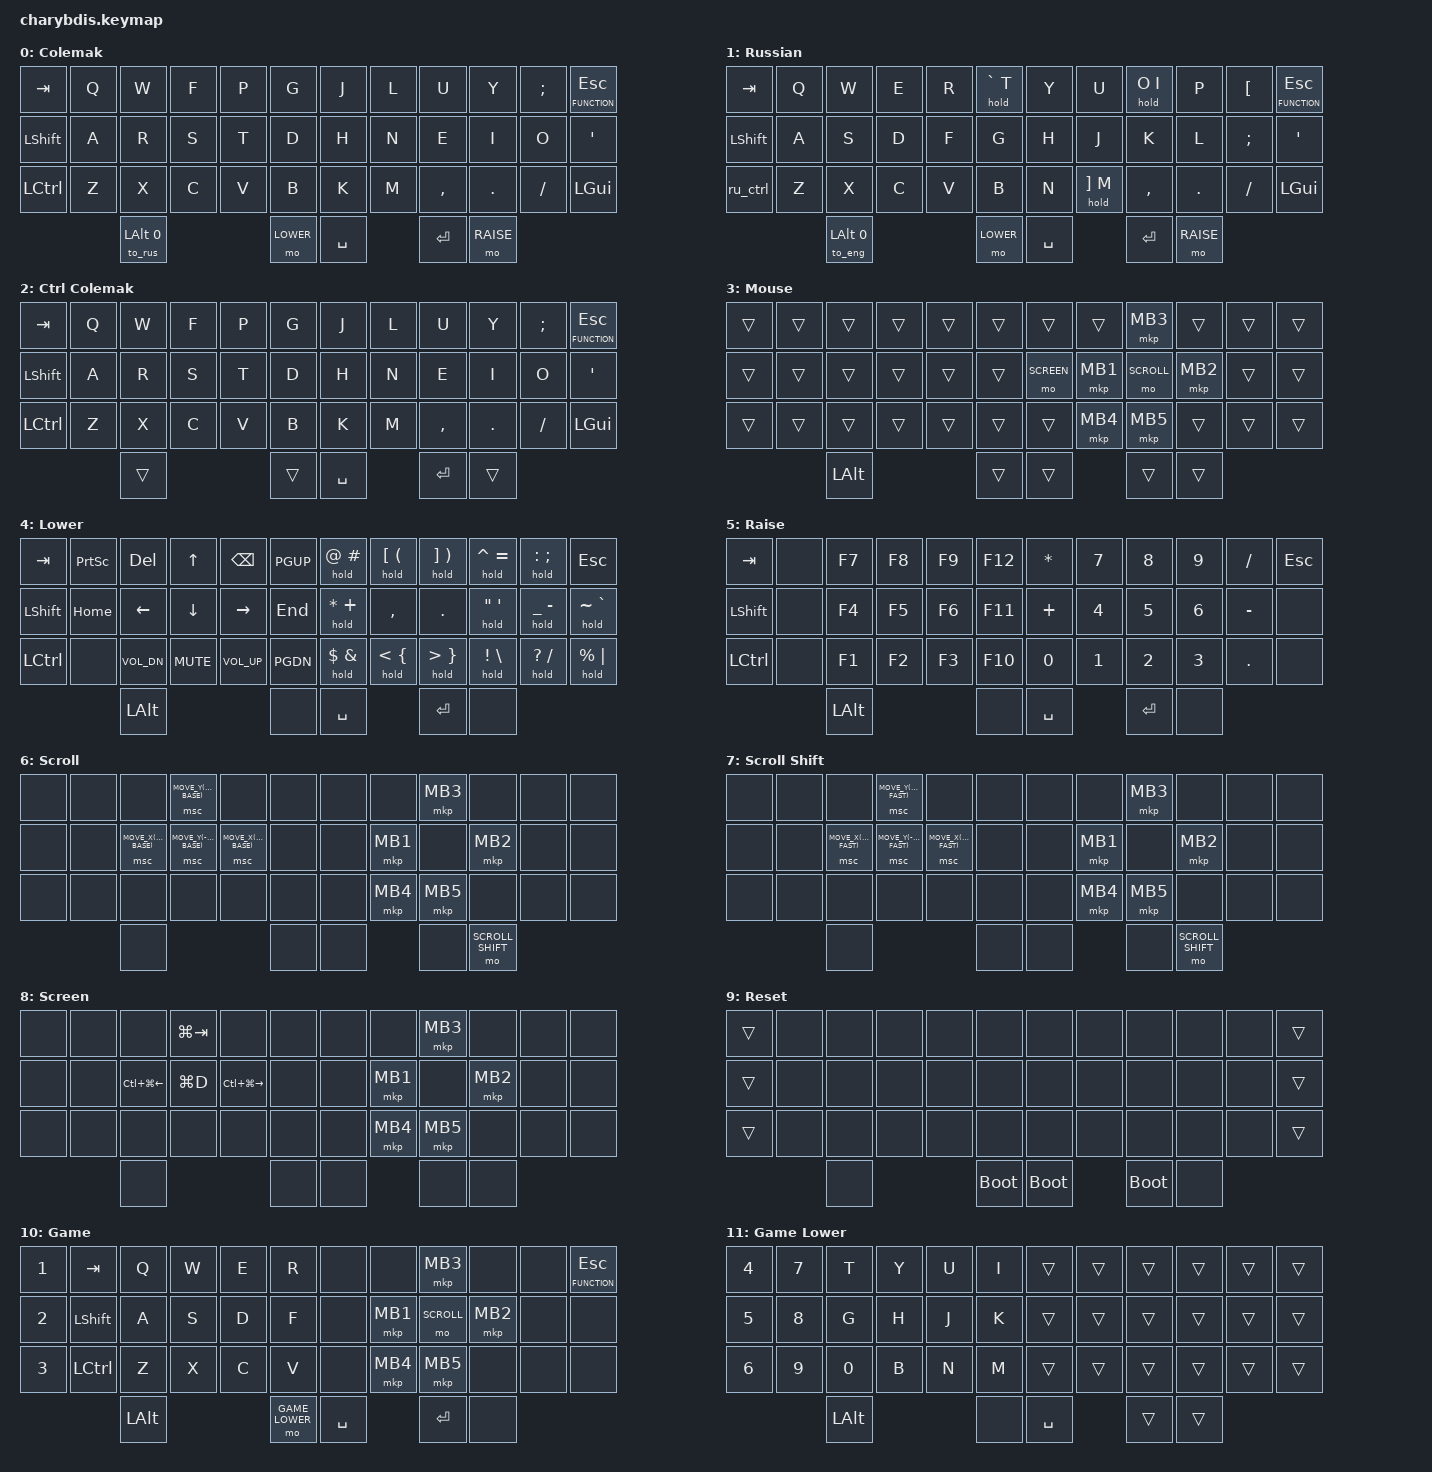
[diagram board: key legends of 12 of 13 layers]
#include <behaviors.dtsi>
#include <dt-bindings/zmk/keys.h>
#include <dt-bindings/zmk/pointing.h>
#include "behaviors/behavior_esc_layer_switch.dtsi"
#include "behaviors/behavior_ru_ctrl.dtsi"

#define COLEMAK 0
#define RUSSIAN 1
#define CTRL_COLEMAK 2
#define MOUSE 3
#define LOWER 4
#define RAISE 5
#define SCROLL 6
#define SCROLL_SHIFT 7
#define SCREEN 8
#define RESET 9
#define GAME 10
#define GAME_LOWER 11
#define FUNCTION 12

#define MOVE_BASE (ZMK_POINTING_DEFAULT_MOVE_VAL)
/* Legacy wheel ticks (smooth scroll off on dongle — ZMK #3383). *16 was hi-res only. */
#define SCROLL_BASE (ZMK_POINTING_DEFAULT_SCRL_VAL / 2)
#define SCROLL_FAST (SCROLL_BASE * 3)

/ {
  combos {
    compatible = "zmk,combos";
    timeout-ms = <20>;
    require-prior-idle-ms = <250>;

    combo_reset_layer_left {
      key-positions = <20 24>;
      bindings = <&to RESET>;
    };
    combo_reset_layer_right {
      key-positions = <25 29>;
      bindings = <&to RESET>;
    };
    combo_reset_central {
      key-positions = <37 38>;
      bindings = <&bootloader>;
      require-prior-idle-ms = <2000>;
    };
    combo_esc {
      key-positions = <1 2>;
      bindings = <&kp ESCAPE>;
    };
    combo_tab {
      key-positions = <2 3>;
      bindings = <&kp TAB>;
    };
    combo_cdel {
      key-positions = <11 12>;
      bindings = <&kp LC(BACKSPACE)>;
    };
    combo_unlock {
      key-positions = <0 4>;
      bindings = <&studio_unlock>;
    };
  };

  chosen {
    zmk,physical-layout = &charybdis_6col_layout;
  };

  keymap {
    compatible = "zmk,keymap";

    Colemak {
      display-name = "Colemak";
      bindings = <
        &kp TAB    &kp Q  &kp W  &kp F  &kp P  &kp G     &kp J  &kp L  &kp U     &kp Y    &kp SEMI  &lt FUNCTION ESCAPE
        &kp LSHFT  &kp A  &kp R  &kp S  &kp T  &kp D     &kp H  &kp N  &kp E     &kp I    &kp O     &kp SQT
        &kp LCTRL  &kp Z  &kp X  &kp C  &kp V  &kp B     &kp K  &kp M  &kp COMMA &kp DOT  &kp FSLH  &kp LGUI
                            &to_rus LALT 0  &mo LOWER  &kp SPACE     &kp RET  &mo RAISE
      >;
    };

    Russian {
      display-name = "Russian";
      bindings = <
        &kp TAB    &kp Q  &kp W  &kp E  &kp R  &hold GRAVE T  &kp Y  &kp U       &hold O I   &kp P    &kp LBKT  &lt FUNCTION ESCAPE
        &kp LSHFT  &kp A  &kp S  &kp D  &kp F  &kp G          &kp H  &kp J       &kp K       &kp L    &kp SEMI  &kp SQT
        &ru_ctrl  &kp Z  &kp X  &kp C  &kp V  &kp B          &kp N  &hold RBKT M &kp COMMA  &kp DOT  &kp FSLH  &kp LGUI
                            &to_eng LALT 0  &mo LOWER  &kp SPACE     &kp RET  &mo RAISE
      >;
    };

    /* Below Mouse/Lower/Raise so Ctrl-first chords still see those layers. */
    CtrlColemak {
      display-name = "Ctrl Colemak";
      bindings = <
        &kp TAB    &kp Q  &kp W  &kp F  &kp P  &kp G     &kp J  &kp L  &kp U     &kp Y    &kp SEMI  &lt FUNCTION ESCAPE
        &kp LSHFT  &kp A  &kp R  &kp S  &kp T  &kp D     &kp H  &kp N  &kp E     &kp I    &kp O     &kp SQT
        &kp LCTRL  &kp Z  &kp X  &kp C  &kp V  &kp B     &kp K  &kp M  &kp COMMA &kp DOT  &kp FSLH  &kp LGUI
                            &trans  &trans  &kp SPACE     &kp RET  &trans
      >;
    };

    Mouse {
      display-name = "Mouse";
      bindings = <
        &trans  &trans  &trans  &trans  &trans  &trans     &trans  &trans   &mkp MB3  &trans   &trans  &trans
        &trans  &trans  &trans  &trans  &trans  &trans     &mo SCREEN  &mkp MB1  &mo SCROLL  &mkp MB2  &trans  &trans
        &trans  &trans  &trans  &trans  &trans  &trans     &trans  &mkp MB4  &mkp MB5  &trans   &trans  &trans
                        &kp LALT  &trans  &trans     &trans  &trans
      >;
    };

    Lower {
      display-name = "Lower";
      bindings = <
        &kp TAB    &kp PSCRN  &kp DEL  &kp UP  &kp BSPC  &kp PGUP     &hold AT HASH  &hold LBKT LPAR  &hold RBKT RPAR  &hold CARET EQUAL  &hold COLON SEMI  &kp ESCAPE
        &kp LSHFT  &kp HOME   &kp LEFT &kp DOWN &kp RIGHT &kp END      &hold ASTRK PLUS  &kp COMMA  &kp DOT  &hold DQT SQT  &hold UNDER MINUS  &hold TILDE GRAVE
        &kp LCTRL  &none      &kp C_VOL_DN  &kp C_MUTE  &kp C_VOL_UP  &kp PGDN   &hold DLLR AMPS  &hold LT LBRC  &hold GT RBRC  &hold EXCL BSLH  &hold QMARK FSLH  &hold PRCNT PIPE
                                &kp LALT  &none  &kp SPACE  &kp RET  &none
      >;
    };

    Raise {
      display-name = "Raise";
      bindings = <
        &kp TAB    &none  &kp F7  &kp F8  &kp F9  &kp F12     &kp ASTRK  &kp N7  &kp N8  &kp N9  &kp FSLH  &kp ESCAPE
        &kp LSHFT  &none  &kp F4  &kp F5  &kp F6  &kp F11     &kp PLUS  &kp N4  &kp N5  &kp N6  &kp MINUS  &none
        &kp LCTRL  &none  &kp F1  &kp F2  &kp F3  &kp F10     &kp N0    &kp N1  &kp N2  &kp N3  &kp DOT   &none
                            &kp LALT  &none  &kp SPACE  &kp RET  &none
      >;
    };

    Scroll {
      display-name = "Scroll";
      bindings = <
        &none  &none  &none  &msc MOVE_Y(SCROLL_BASE)   &none  &none     &none  &none   &mkp MB3  &none  &none  &none
        &none  &none  &msc MOVE_X(-SCROLL_BASE) &msc MOVE_Y(-SCROLL_BASE) &msc MOVE_X(SCROLL_BASE) &none  &none  &mkp MB1  &none  &mkp MB2  &none  &none
        &none  &none  &none  &none  &none  &none     &none  &mkp MB4  &mkp MB5  &none  &none  &none
                        &none  &none  &none     &none  &mo SCROLL_SHIFT
      >;
    };

    ScrollShift {
      display-name = "Scroll Shift";
      bindings = <
        &none  &none  &none  &msc MOVE_Y(SCROLL_FAST)   &none  &none     &none  &none   &mkp MB3  &none  &none  &none
        &none  &none  &msc MOVE_X(-SCROLL_FAST) &msc MOVE_Y(-SCROLL_FAST) &msc MOVE_X(SCROLL_FAST) &none  &none  &mkp MB1  &none  &mkp MB2  &none  &none
        &none  &none  &none  &none  &none  &none     &none  &mkp MB4  &mkp MB5  &none  &none  &none
                        &none  &none  &none     &none  &mo SCROLL_SHIFT
      >;
    };

    Screen {
      display-name = "Screen";
      bindings = <
        &none  &none  &none  &kp LG(TAB)   &none  &none     &none  &none   &mkp MB3  &none  &none  &none
        &none  &none  &kp LC(LG(LEFT))  &kp LG(D)  &kp LC(LG(RIGHT))  &none  &none  &mkp MB1  &none  &mkp MB2  &none  &none
        &none  &none  &none  &none  &none  &none     &none  &mkp MB4  &mkp MB5  &none  &none  &none
                        &none  &none  &none     &none  &none
      >;
    };

    Reset {
      display-name = "Reset";
      bindings = <
        &trans  &none  &none  &none  &none  &none     &none  &none  &none  &none  &none  &trans
        &trans  &none  &none  &none  &none  &none     &none  &none  &none  &none  &none  &trans
        &trans  &none  &none  &none  &none  &none     &none  &none  &none  &none  &none  &trans
                        &none  &bootloader  &bootloader     &bootloader  &none
      >;
    };

    Game {
      display-name = "Game";
      bindings = <
        &kp N1    &kp TAB    &kp Q  &kp W  &kp E  &kp R     &none  &none  &mkp MB3  &none  &none  &lt FUNCTION ESCAPE
        &kp N2    &kp LSHFT  &kp A  &kp S  &kp D  &kp F     &none  &mkp MB1  &mo SCROLL  &mkp MB2  &none  &none
        &kp N3    &kp LCTRL  &kp Z  &kp X  &kp C  &kp V     &none  &mkp MB4  &mkp MB5  &none  &none  &none
                            &kp LALT  &mo GAME_LOWER  &kp SPACE     &kp RET  &none
      >;
    };

    GameLower {
      display-name = "Game Lower";
      bindings = <
        &kp N4  &kp N7  &kp T  &kp Y  &kp U  &kp I     &trans  &trans  &trans  &trans  &trans  &trans
        &kp N5  &kp N8  &kp G  &kp H  &kp J  &kp K     &trans  &trans  &trans  &trans  &trans  &trans
        &kp N6  &kp N9  &kp N0  &kp B  &kp N  &kp M     &trans  &trans  &trans  &trans  &trans  &trans
                        &kp LALT  &none  &kp SPACE     &trans  &trans
      >;
    };

    Fun {
      display-name = "Function";
      bindings = <
        &none  &none  &none  &none  &none  &none     &to COLEMAK  &to GAME  &none  &none  &none  &none
        &none  &none  &none  &none  &none  &none     &none  &none  &none  &none  &none  &none
        &none  &none  &none  &none  &none  &none     &none  &none  &none  &none  &none  &none
                        &none  &none  &none     &none  &none
      >;
    };
  };
};
